# SC32F12XRX48 register map
File version: 1.0
CPU: CM0+ r0p1, little endian, MPU, no FPU, 4 interrupt priority bits
Registers are 32-bit, read-write, reset 0x0 unless marked. A register's access mark holds for its fields unless they carry their own. Offsets are from the block's base; [hi:lo] are bit positions; {n}, {i} and the like mark numbered series.

## SPI0 — Serial peripheral interface/Inter-IC sound
Base 0x40020040
Same registers: SPI1 0x40021040, SPI2 0x400210A0
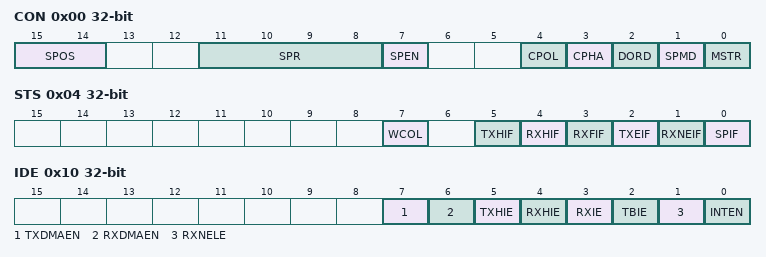
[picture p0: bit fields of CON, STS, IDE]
0x00 CON — control register
  [15:14] SPOS — Select mapping ports
  [11:8] SPR — Spi clock select
  [7] SPEN — Hardware SPI calculation enable
  [4] CPOL — The clock polarity
  [3] CPHA — The clock phase
  [2] DORD — Transfer direction
  [1] SPMD — Transport mode
  [0] MSTR — Master selection
0x04 STS — Stauts register
  [7] WCOL — Written to the conflict
  [5] TXHIF ro — Tx buffer half full flag
  [4] RXHIF ro — Rx buffer half full flag
  [3] RXFIF ro — Rx buffer full flag
  [2] TXEIF — Tx buffer enable flag
  [1] RXNEIF — Rx buffer enable flag
  [0] SPIF — SPI interrupt flag
0x0C DATA — DATA Buffer register
  [15:0] SPD — Send buffer data
0x10 IDE — DMA Control register
  [7] TXDMAEN — Tx trig DMA interrput enable
  [6] RXDMAEN — Rx trig DMA interrput enable
  [5] TXHIE — Tx buffer interrput enable
  [4] RXHIE — Rx buffer interrput enable
  [3] RXIE — FIFO buffer over interrput enable
  [2] TBIE — Tx buffer empty interrput enable
  [1] RXNELE — Rx not empty interrupt enable
  [0] INTEN — Interrput mask enable

## BTM
Base 0x40022100
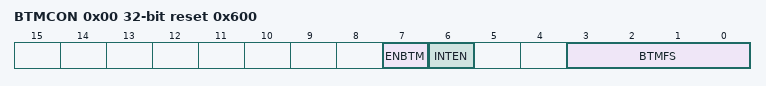
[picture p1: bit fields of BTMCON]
0x00 BTMCON reset 0x600 — BTM control register
  [7] ENBTM — Low-frequency Base Timer start control bit
  [6] INTEN — Interrupt enable bit of the request CPU
  [3:0] BTMFS — Low-frequency clock interrupt frequency selection bits
0x04 STS — BTM flag register
  [0] BTMIF — Base Timer interrupt application flag bit

## LCD_LED
Base 0x40022280
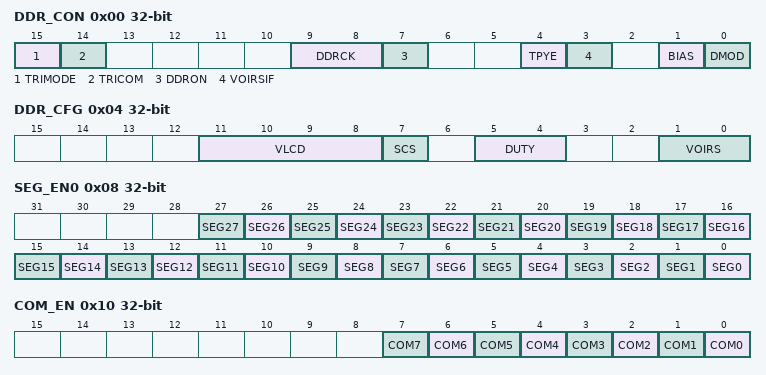
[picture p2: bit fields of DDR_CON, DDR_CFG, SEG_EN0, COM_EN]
0x00 DDR_CON — Display driver Control Register
  [15] TRIMODE — The custom frame mode
  [14] TRICOM — The custom frame
  [9:8] DDRCK — Display driver clock
  [7] DDRON — Display driver enable
  [4] TPYE — LCD waveform tpye
  [3] VOIRSIF — LCD fast charge
  [1] BIAS — BIAS Set
  [0] DMOD — Display mode
0x04 DDR_CFG — Display driver Configuration Register
  [11:8] VLCD — Voltage LCD offset
  [7] SCS — Seg Com select
  [5:4] DUTY — DUTY Mode
  [1:0] VOIRS — voltage resistance select
0x08 SEG_EN0 — SEG enable register
  [n] SEG{n} (n=0..27)
0x10 COM_EN — COM enable register
  [n] COM{n} (n=0..7)

## CMP — Analog comparator
Base 0x40022130
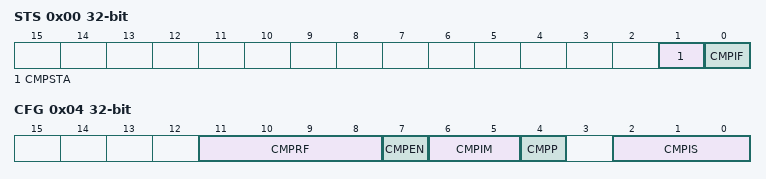
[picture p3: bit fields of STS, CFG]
0x00 STS — ACMP status register
  [1] CMPSTA ro — ACMP output status bit
  [0] CMPIF — ACMP interrupt flag bit
0x04 CFG — ACMP config register
  [11:8] CMPRF — ACMP negative-end comparison voltage selection
  [7] CMPEN — ACMP enable bit
  [6:5] CMPIM — ACMP interrupt mode selection
  [4] CMPP — ACMP input selection
  [2:0] CMPIS — ACMP input channel selection

## TK — TK touch
Base 0x40022200
0x00 TK_CHN0 — TK Channel 0 register
  [31:0] TK31_TK0 — TK0 to TK31 channel ENABLE
0x04 TK_CHN1 — TK Channel 1 register
  [5:0] TK38_TK32 — TK32 to TK38 channel ENABLE
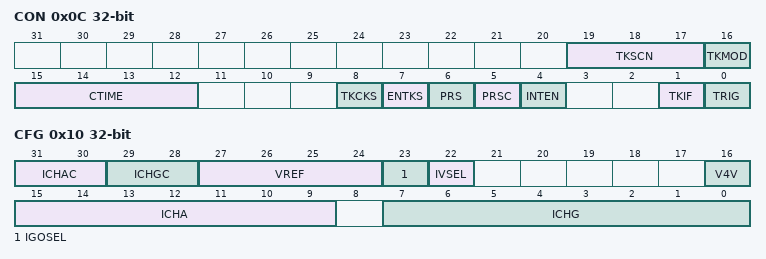
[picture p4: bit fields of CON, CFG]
0x0C CON — TK control register
  [19:17] TKSCN — TK waveform selection
  [16] TKMOD — TK Mode
  [15:12] CTIME — Scan Time
  [8] TKCKS — TK CLOCKS
  [7] ENTKS — Enable TK
  [6] PRS
  [5] PRSC — PRS BIT
  [4] INTEN — Interrput enable
  [1] TKIF — TK scan flag
  [0] TRIG — TK Trig
0x10 CFG — Configuration register
  [31:30] ICHAC — ICHAC Selector
  [29:28] ICHGC — ICHGC Selector
  [27:24] VREF — V-REFerence Selector
  [23] IGOSEL — Option select
  [22] IVSEL — Current voltage select
  [16] V4V
  [15:9] ICHA
  [7:0] ICHG
0x18 CNT — TK count register
  [15:0] TKCNT
0x1C TM — Timing prset register
  [15:0] TKTM

## OP — operational amplifier
Base 0x40022140
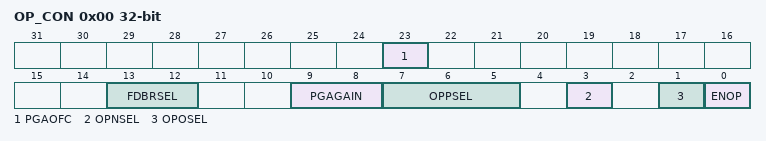
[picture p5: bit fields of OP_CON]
0x00 OP_CON — control register
  [23] PGAOFC — PGA Offset INPUT Control
  [13:12] FDBRSEL — Feedback resistor end connection selection bit
  [9:8] PGAGAIN
  [7:5] OPPSEL — OP positive select
  [3] OPNSEL — OP NEGATIVE SELECT
  [1] OPOSEL — OP PORT SELECT
  [0] ENOP — OP AMP enable
